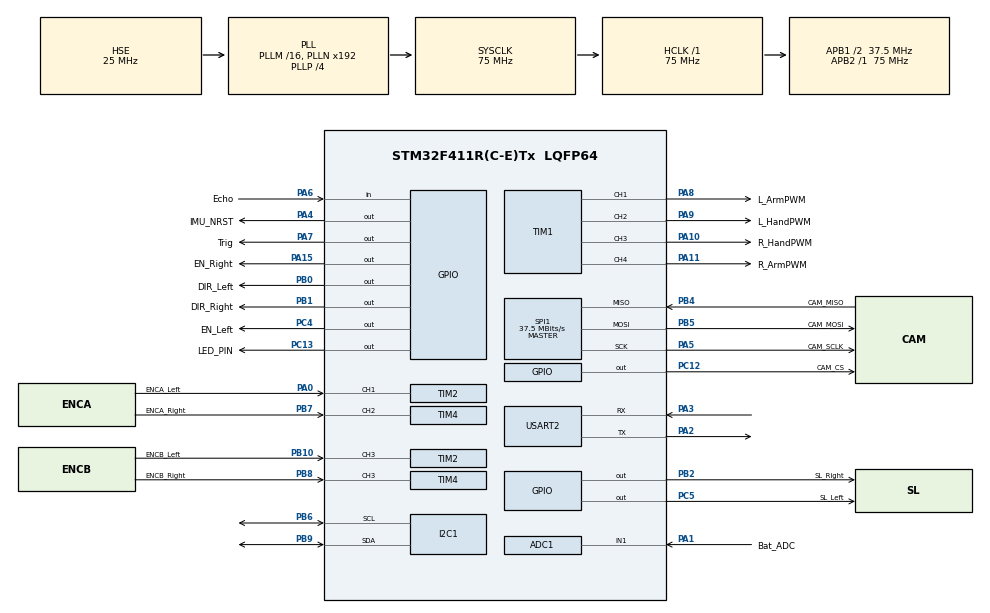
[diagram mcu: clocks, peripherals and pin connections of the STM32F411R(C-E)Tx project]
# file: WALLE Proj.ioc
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ADC1.Channel-0\#ChannelRegularConversion=ADC_CHANNEL_1
ADC1.NbrOfConversionFlag=1
ADC1.Rank-0\#ChannelRegularConversion=1
ADC1.SamplingTime-0\#ChannelRegularConversion=ADC_SAMPLETIME_3CYCLES
ADC1.master=1
Mcu.Family=STM32F4
Mcu.Name=STM32F411R(C-E)Tx
Mcu.Package=LQFP64
NVIC.PriorityGroup=NVIC_PRIORITYGROUP_4
NVIC.RCC_IRQn=true\:0\:0\:false\:false\:true\:true\:false\:true
NVIC.TIM5_IRQn=true\:0\:0\:false\:false\:true\:true\:true\:true
PA0-WKUP.GPIO_Label=ENCA_Left
PA0-WKUP.Signal=S_TIM2_CH1_ETR
PA1.GPIO_Label=Bat_ADC
PA1.Signal=ADCx_IN1
PA10.GPIO_Label=R_HandPWM
PA10.Signal=S_TIM1_CH3
PA11.GPIO_Label=R_ArmPWM
PA11.Signal=S_TIM1_CH4
PA13.Mode=Trace_Asynchronous_SW
PA13.Signal=SYS_JTMS-SWDIO
PA14.Mode=Trace_Asynchronous_SW
PA14.Signal=SYS_JTCK-SWCLK
PA15.GPIO_Label=EN_Right
PA15.Signal=GPIO_Output
PA2.Mode=Asynchronous
PA2.Signal=USART2_TX
PA3.Mode=Asynchronous
PA3.Signal=USART2_RX
PA4.GPIO_Label=IMU_NRST
PA4.Signal=GPIO_Output
PA5.GPIO_Label=CAM_SCLK
PA5.Mode=Full_Duplex_Master
PA5.Signal=SPI1_SCK
PA6.GPIO_Label=Echo
PA6.Signal=GPIO_Input
PA7.GPIO_Label=Trig
PA7.Signal=GPIO_Output
PA8.GPIO_Label=L_ArmPWM
PA8.Signal=S_TIM1_CH1
PA9.GPIO_Label=L_HandPWM
PA9.Signal=S_TIM1_CH2
PB0.GPIO_Label=DIR_Left
PB0.Signal=GPIO_Output
PB1.GPIO_Label=DIR_Right
PB1.Signal=GPIO_Output
PB10.GPIO_Label=ENCB_Left
PB10.Signal=S_TIM2_CH3
PB2.GPIO_Label=SL_Right
PB2.Signal=GPIO_Output
PB3.Mode=Trace_Asynchronous_SW
PB3.Signal=SYS_JTDO-SWO
PB4.GPIO_Label=CAM_MISO
PB4.Mode=Full_Duplex_Master
PB4.Signal=SPI1_MISO
PB5.GPIO_Label=CAM_MOSI
PB5.Mode=Full_Duplex_Master
PB5.Signal=SPI1_MOSI
PB6.Mode=I2C
PB6.Signal=I2C1_SCL
PB7.GPIO_Label=ENCA_Right
PB7.Signal=S_TIM4_CH2
PB8.GPIO_Label=ENCB_Right
PB8.Signal=S_TIM4_CH3
PB9.Mode=I2C
PB9.Signal=I2C1_SDA
PC12.GPIO_Label=CAM_CS
PC12.Signal=GPIO_Output
PC13-ANTI_TAMP.GPIO_Label=LED_PIN
PC13-ANTI_TAMP.Signal=GPIO_Output
PC4.GPIO_Label=EN_Left
PC4.Signal=GPIO_Output
PC5.GPIO_Label=SL_Left
PC5.Signal=GPIO_Output
PH0\ -\ OSC_IN.Mode=HSE-External-Oscillator
PH0\ -\ OSC_IN.Signal=RCC_OSC_IN
PH1\ -\ OSC_OUT.Mode=HSE-External-Oscillator
PH1\ -\ OSC_OUT.Signal=RCC_OSC_OUT
ProjectManager.HeapSize=0x200
ProjectManager.StackSize=0x400
ProjectManager.TargetToolchain=STM32CubeIDE
RCC.48MHZClocksFreq_Value=75000000
RCC.AHBFreq_Value=75000000
RCC.APB1CLKDivider=RCC_HCLK_DIV2
RCC.APB1Freq_Value=37500000
RCC.APB1TimFreq_Value=75000000
RCC.APB2Freq_Value=75000000
RCC.APB2TimFreq_Value=75000000
RCC.CortexFreq_Value=75000000
RCC.HCLKFreq_Value=75000000
RCC.HSE_VALUE=25000000
RCC.HSI_VALUE=16000000
RCC.LSE_VALUE=32768
RCC.PLLP=RCC_PLLP_DIV4
RCC.PLLSourceVirtual=RCC_PLLSOURCE_HSE
RCC.SYSCLKFreq_VALUE=75000000
RCC.SYSCLKSource=RCC_SYSCLKSOURCE_PLLCLK
RCC.VCOOutputFreq_Value=300000000
SH.ADCx_IN1.0=ADC1_IN1,IN1
SH.S_TIM1_CH1.0=TIM1_CH1,PWM Generation1 CH1
SH.S_TIM1_CH2.0=TIM1_CH2,PWM Generation2 CH2
SH.S_TIM1_CH3.0=TIM1_CH3,PWM Generation3 CH3
SH.S_TIM1_CH4.0=TIM1_CH4,PWM Generation4 CH4
SH.S_TIM2_CH1_ETR.0=TIM2_CH1,Input_Capture1_from_TI1
SH.S_TIM2_CH3.0=TIM2_CH3,Input_Capture3_from_TI3
SH.S_TIM4_CH2.0=TIM4_CH2,Input_Capture2_from_TI2
SH.S_TIM4_CH3.0=TIM4_CH3,Input_Capture3_from_TI3
SPI1.BaudRatePrescaler=SPI_BAUDRATEPRESCALER_2
SPI1.CalculateBaudRate=37.5 MBits/s
SPI1.Direction=SPI_DIRECTION_2LINES
SPI1.Mode=SPI_MODE_MASTER
SPI1.VirtualType=VM_MASTER
TIM1.Channel-PWM\ Generation1\ CH1=TIM_CHANNEL_1
TIM1.Channel-PWM\ Generation2\ CH2=TIM_CHANNEL_2
TIM1.Channel-PWM\ Generation3\ CH3=TIM_CHANNEL_3
TIM1.Channel-PWM\ Generation4\ CH4=TIM_CHANNEL_4
TIM2.Channel-Input_Capture1_from_TI1=TIM_CHANNEL_1
TIM2.Channel-Input_Capture3_from_TI3=TIM_CHANNEL_3
TIM4.Channel-Input_Capture2_from_TI2=TIM_CHANNEL_2
TIM4.Channel-Input_Capture3_from_TI3=TIM_CHANNEL_3
TIM5.Period=99
TIM5.Prescaler=15
USART2.VirtualMode=VM_ASYNC
VP_TIM3_VS_ClockSourceINT.Mode=Internal
VP_TIM5_VS_ClockSourceINT.Mode=Internal
board=custom

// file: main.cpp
/* USER CODE BEGIN Header */
/**
  ******************************************************************************
  * @file           : main.c
  * @brief          : Main program body
  ******************************************************************************
  * @attention
  *
  * Copyright (c) 2025 STMicroelectronics.
  * All rights reserved.
  *
  * This software is licensed under terms that can be found in the LICENSE file
  * in the root directory of this software component.
  * If no LICENSE file comes with this software, it is provided AS-IS.
  *
  ******************************************************************************
  */
/* USER CODE END Header */
#include "main.h"
#include "main.h"
#include "batteryMonitor.h"
#include "WALLE_FSM.h"
#include <string.h>
#include <unistd.h>
#include <stdio.h>

ADC_HandleTypeDef hadc1;

I2C_HandleTypeDef hi2c1;

SPI_HandleTypeDef hspi1;

TIM_HandleTypeDef htim1;
TIM_HandleTypeDef htim2;
TIM_HandleTypeDef htim3;
TIM_HandleTypeDef htim4;
TIM_HandleTypeDef htim5;

UART_HandleTypeDef huart2;

/*Global Motors for interrupt updates*/
RomiMotor rightMotor(GPIOA, EN_Right_Pin, GPIOB, DIR_Right_Pin, GPIOB, SL_Right_Pin);
RomiMotor leftMotor(GPIOC, EN_Left_Pin, GPIOB, DIR_Left_Pin, GPIOC, SL_Left_Pin);

void SystemClock_Config(void);
static void MX_GPIO_Init(void);
static void MX_ADC1_Init(void);
static void MX_I2C1_Init(void);
static void MX_TIM1_Init(void);
static void MX_TIM2_Init(void);
static void MX_TIM4_Init(void);
static void MX_USART2_UART_Init(void);
static void MX_TIM3_Init(void);
static void MX_SPI1_Init(void);
static void MX_TIM5_Init(void);

#ifndef WALL_E_FUNC
#define WALL_E_FUNC
void WALL_E_systemCheck(BatteryMonitor&, HCSR04&, RomiMotor&, RomiMotor&, BNO055&, OV2640Camera&);
#endif
/* USER CODE BEGIN PFP */
#define OV2640_I2C_ADDR 0x60  // 0x30 << 1

/* USER CODE END PFP */

/* USER CODE BEGIN 0 */
void printToUART(const char* msg) {
    HAL_UART_Transmit(&huart2, (uint8_t*)msg, strlen(msg), HAL_MAX_DELAY);
}

void simpleMovements(){
	rightMotor.setSpeed(10);
	leftMotor.setSpeed(-10);
	HAL_Delay(1000);
	rightMotor.setSpeed(-5);
	HAL_Delay(500);
	rightMotor.setSpeed(10);
	HAL_Delay(700);
	leftMotor.setSpeed(0);
	rightMotor.setSpeed(0);
}
/* USER CODE END 0 */

int main(void)
{

  /* MCU Configuration--------------------------------------------------------*/

  /* Reset of all peripherals, Initializes the Flash interface and the Systick. */
  HAL_Init();

  /* Configure the system clock */
  SystemClock_Config();

  /* Initialize all configured peripherals */
  MX_GPIO_Init();
  MX_ADC1_Init();
  MX_I2C1_Init();
  MX_TIM1_Init();
  MX_TIM2_Init();
  MX_TIM4_Init();
  MX_USART2_UART_Init();
  MX_TIM3_Init();
  MX_SPI1_Init();
  MX_TIM5_Init();

  HAL_NVIC_SetPriority(TIM5_IRQn, 0, 0);
  HAL_NVIC_EnableIRQ(TIM5_IRQn);

  /*Peripherals Instantiation*/
  BatteryMonitor batteryMonitor(&hadc1, 7000);
  HCSR04 rangeFinder(GPIOA, Trig_Pin, Echo_GPIO_Port, Echo_Pin, &htim3);
  BNO055 imu(&hi2c1, (uint8_t) 0x28);
  OV2640Camera camera(&hi2c1, &hspi1, GPIOC, CAM_CS_Pin);
  Servo rightArm(&htim1, TIM_CHANNEL_4);
  Servo rightHand(&htim1, TIM_CHANNEL_3);
  Servo leftArm(&htim1, TIM_CHANNEL_1);
  Servo leftHand(&htim1, TIM_CHANNEL_2);
  rightArm.attach();
  rightHand.attach();
  leftArm.attach();
  leftHand.attach();

  WALL_E_systemCheck(batteryMonitor, rangeFinder, rightMotor, leftMotor, imu, camera);
  printToUART("Entering WALL-E FSM\r\n");

  WALLE walleFSM(imu, rangeFinder, leftMotor, rightMotor, camera, leftArm, leftHand,
		  rightArm, rightHand);

  walleFSM.init();
  uint32_t lastTick = HAL_GetTick();

  while(1){
	  uint32_t currentTick = HAL_GetTick();
	  float dt = (currentTick - lastTick);
	  lastTick = currentTick;

	  walleFSM.update(dt);

	  HAL_Delay(5);
  }

}

/*
 * @brief Function Performs System Peipherals Check
 * @return None
 */
void WALL_E_systemCheck(BatteryMonitor& bat, HCSR04& range, RomiMotor& rMotor, RomiMotor& lMotor, BNO055& imu, OV2640Camera& camera){
	  imu.init_imu();
	  char buffer[1024];
	  uint8_t sys, gyro, accel, mag;
	  while (true) {
		  imu.readCalibStatus(sys, gyro, accel, mag);
		  if (sys == 3 && gyro == 3){
			  int len = sprintf(buffer, "IMU Calibrated Sys: %d Gyro: %d\r\n", sys, gyro);
			  HAL_UART_Transmit(&huart2, (uint8_t *)buffer, len, 10);
			  memset(buffer, 0, sizeof(buffer));
			  break;
		  }
		  int len = sprintf(buffer, "Sys %d, Gyro %d, Accel %d, Mag %d\r\n", sys, gyro, accel, mag);
		  HAL_UART_Transmit(&huart2, (uint8_t *)buffer, len, 10);
		  memset(buffer, 0, sizeof(buffer));
		  HAL_Delay(500);
	  }

	  /*UltraSonic Sensor Timer*/
	  HAL_TIM_Base_Start(&htim3);

	  /*Interrupt Timer for PWM Signal for Motors*/
	  rMotor.enable();
	  rMotor.setSpeed(0);
	  lMotor.enable();
	  lMotor.setSpeed(0);
	  HAL_TIM_Base_Start_IT(&htim5);
	  int len = sprintf(buffer, "Motors Enabled, Speed Set to 0.\r\n");
	  HAL_UART_Transmit(&huart2, (uint8_t *)buffer, len, 10);
	  memset(buffer, 0, sizeof(buffer));

	  /*Battery Check*/
	  len = sprintf(buffer, "Battery Voltage is at %u mV\r\nChecking RangeSensor\r\n", bat.getVoltage_mV());
	  HAL_UART_Transmit(&huart2, (uint8_t *)buffer, len, 10);
	  memset(buffer, 0, sizeof(buffer));

	  /*Range Sensor Check*/
	  while(true){
		  bool success = range.measure();
		  if (success){
				  uint32_t d = range.getDistanceCm();
				  len = sprintf(buffer, "\tDistance is %lu cm\r\n", d);
				  HAL_UART_Transmit(&huart2, (uint8_t *)buffer, len, 10);
				  memset(buffer, 0, sizeof(buffer));
				  break;
		  HAL_Delay(500);
		  }
	  }

	  /*Camera Check*/
	  printToUART("Camera I2C Check and initialization\r\n");
	  uint8_t pid = 0, ver = 0;
	  HAL_I2C_Mem_Read(&hi2c1, OV2640_I2C_ADDR, 0x0A, I2C_MEMADD_SIZE_8BIT, &pid, 1, HAL_MAX_DELAY);
	  HAL_I2C_Mem_Read(&hi2c1, OV2640_I2C_ADDR, 0x0B, I2C_MEMADD_SIZE_8BIT, &ver, 1, HAL_MAX_DELAY);

	  char buf[64];
	  snprintf(buf, sizeof(buf), "\tOV2640 PID: 0x%02X, VER: 0x%02X\r\n", pid, ver);
	  HAL_UART_Transmit(&huart2, (uint8_t*)buf, strlen(buf), HAL_MAX_DELAY);
	  while(true){
		  bool success = camera.initialize();
		  if (success){
			  printToUART("\tCamera Initialized. Ready to Detect\r\n");
			  break;
		  }
	  }

}

/*
 * @brief Function is the interrupt Callback for the Updates on the Motor PWM signals
 * @return None
 */
void HAL_TIM_PeriodElapsedCallback(TIM_HandleTypeDef *htim) {
    if (htim->Instance == TIM5) {
        // Your motor PWM logic here
    	rightMotor.updatePWM();
        leftMotor.updatePWM();
    }
}
void SystemClock_Config(void)
{
  RCC_OscInitTypeDef RCC_OscInitStruct = {0};
  RCC_ClkInitTypeDef RCC_ClkInitStruct = {0};

  /** Configure the main internal regulator output voltage
  */
  __HAL_RCC_PWR_CLK_ENABLE();
  __HAL_PWR_VOLTAGESCALING_CONFIG(PWR_REGULATOR_VOLTAGE_SCALE1);

  /** Initializes the RCC Oscillators according to the specified parameters
  * in the RCC_OscInitTypeDef structure.
  */
  RCC_OscInitStruct.OscillatorType = RCC_OSCILLATORTYPE_HSE;
  RCC_OscInitStruct.HSEState = RCC_HSE_ON;
  RCC_OscInitStruct.PLL.PLLState = RCC_PLL_ON;
  RCC_OscInitStruct.PLL.PLLSource = RCC_PLLSOURCE_HSE;
  RCC_OscInitStruct.PLL.PLLM = 16;
  RCC_OscInitStruct.PLL.PLLN = 192;
  RCC_OscInitStruct.PLL.PLLP = RCC_PLLP_DIV4;
  RCC_OscInitStruct.PLL.PLLQ = 4;
  if (HAL_RCC_OscConfig(&RCC_OscInitStruct) != HAL_OK)
  {
    Error_Handler();
  }

  /** Initializes the CPU, AHB and APB buses clocks
  */
  RCC_ClkInitStruct.ClockType = RCC_CLOCKTYPE_HCLK|RCC_CLOCKTYPE_SYSCLK
                              |RCC_CLOCKTYPE_PCLK1|RCC_CLOCKTYPE_PCLK2;
  RCC_ClkInitStruct.SYSCLKSource = RCC_SYSCLKSOURCE_PLLCLK;
  RCC_ClkInitStruct.AHBCLKDivider = RCC_SYSCLK_DIV1;
  RCC_ClkInitStruct.APB1CLKDivider = RCC_HCLK_DIV2;
  RCC_ClkInitStruct.APB2CLKDivider = RCC_HCLK_DIV1;

  if (HAL_RCC_ClockConfig(&RCC_ClkInitStruct, FLASH_LATENCY_2) != HAL_OK)
  {
    Error_Handler();
  }
}

static void MX_ADC1_Init(void)
{

  ADC_ChannelConfTypeDef sConfig = {0};

  /** Configure the global features of the ADC (Clock, Resolution, Data Alignment and number of conversion)
  */
  hadc1.Instance = ADC1;
  hadc1.Init.ClockPrescaler = ADC_CLOCK_SYNC_PCLK_DIV4;
  hadc1.Init.Resolution = ADC_RESOLUTION_12B;
  hadc1.Init.ScanConvMode = DISABLE;
  hadc1.Init.ContinuousConvMode = DISABLE;
  hadc1.Init.DiscontinuousConvMode = DISABLE;
  hadc1.Init.ExternalTrigConvEdge = ADC_EXTERNALTRIGCONVEDGE_NONE;
  hadc1.Init.ExternalTrigConv = ADC_SOFTWARE_START;
  hadc1.Init.DataAlign = ADC_DATAALIGN_RIGHT;
  hadc1.Init.NbrOfConversion = 1;
  hadc1.Init.DMAContinuousRequests = DISABLE;
  hadc1.Init.EOCSelection = ADC_EOC_SINGLE_CONV;
  if (HAL_ADC_Init(&hadc1) != HAL_OK)
  {
    Error_Handler();
  }

  /** Configure for the selected ADC regular channel its corresponding rank in the sequencer and its sample time.
  */
  sConfig.Channel = ADC_CHANNEL_1;
  sConfig.Rank = 1;
  sConfig.SamplingTime = ADC_SAMPLETIME_3CYCLES;
  if (HAL_ADC_ConfigChannel(&hadc1, &sConfig) != HAL_OK)
  {
    Error_Handler();
  }

}

static void MX_I2C1_Init(void)
{

  hi2c1.Instance = I2C1;
  hi2c1.Init.ClockSpeed = 100000;
  hi2c1.Init.DutyCycle = I2C_DUTYCYCLE_2;
  hi2c1.Init.OwnAddress1 = 0;
  hi2c1.Init.AddressingMode = I2C_ADDRESSINGMODE_7BIT;
  hi2c1.Init.DualAddressMode = I2C_DUALADDRESS_DISABLE;
  hi2c1.Init.OwnAddress2 = 0;
  hi2c1.Init.GeneralCallMode = I2C_GENERALCALL_DISABLE;
  hi2c1.Init.NoStretchMode = I2C_NOSTRETCH_DISABLE;
  if (HAL_I2C_Init(&hi2c1) != HAL_OK)
  {
    Error_Handler();
  }

}

static void MX_SPI1_Init(void)
{

  /* SPI1 parameter configuration*/
  hspi1.Instance = SPI1;
  hspi1.Init.Mode = SPI_MODE_MASTER;
  hspi1.Init.Direction = SPI_DIRECTION_2LINES;
  hspi1.Init.DataSize = SPI_DATASIZE_8BIT;
  hspi1.Init.CLKPolarity = SPI_POLARITY_LOW;
  hspi1.Init.CLKPhase = SPI_PHASE_1EDGE;
  hspi1.Init.NSS = SPI_NSS_SOFT;
  hspi1.Init.BaudRatePrescaler = SPI_BAUDRATEPRESCALER_2;
  hspi1.Init.FirstBit = SPI_FIRSTBIT_MSB;
  hspi1.Init.TIMode = SPI_TIMODE_DISABLE;
  hspi1.Init.CRCCalculation = SPI_CRCCALCULATION_DISABLE;
  hspi1.Init.CRCPolynomial = 10;
  if (HAL_SPI_Init(&hspi1) != HAL_OK)
  {
    Error_Handler();
  }

}

static void MX_TIM1_Init(void)
{

  TIM_MasterConfigTypeDef sMasterConfig = {0};
  TIM_OC_InitTypeDef sConfigOC = {0};
  TIM_BreakDeadTimeConfigTypeDef sBreakDeadTimeConfig = {0};

  htim1.Instance = TIM1;
  htim1.Init.Prescaler = 74;
  htim1.Init.CounterMode = TIM_COUNTERMODE_UP;
  htim1.Init.Period = 19999;
  htim1.Init.ClockDivision = TIM_CLOCKDIVISION_DIV1;
  htim1.Init.RepetitionCounter = 0;
  htim1.Init.AutoReloadPreload = TIM_AUTORELOAD_PRELOAD_DISABLE;
  if (HAL_TIM_PWM_Init(&htim1) != HAL_OK)
  {
    Error_Handler();
  }
  sMasterConfig.MasterOutputTrigger = TIM_TRGO_RESET;
  sMasterConfig.MasterSlaveMode = TIM_MASTERSLAVEMODE_DISABLE;
  if (HAL_TIMEx_MasterConfigSynchronization(&htim1, &sMasterConfig) != HAL_OK)
  {
    Error_Handler();
  }
  sConfigOC.OCMode = TIM_OCMODE_PWM1;
  sConfigOC.Pulse = 0;
  sConfigOC.OCPolarity = TIM_OCPOLARITY_HIGH;
  sConfigOC.OCNPolarity = TIM_OCNPOLARITY_HIGH;
  sConfigOC.OCFastMode = TIM_OCFAST_DISABLE;
  sConfigOC.OCIdleState = TIM_OCIDLESTATE_RESET;
  sConfigOC.OCNIdleState = TIM_OCNIDLESTATE_RESET;
  if (HAL_TIM_PWM_ConfigChannel(&htim1, &sConfigOC, TIM_CHANNEL_1) != HAL_OK)
  {
    Error_Handler();
  }
  if (HAL_TIM_PWM_ConfigChannel(&htim1, &sConfigOC, TIM_CHANNEL_2) != HAL_OK)
  {
    Error_Handler();
  }
  if (HAL_TIM_PWM_ConfigChannel(&htim1, &sConfigOC, TIM_CHANNEL_3) != HAL_OK)
  {
    Error_Handler();
  }
  if (HAL_TIM_PWM_ConfigChannel(&htim1, &sConfigOC, TIM_CHANNEL_4) != HAL_OK)
  {
    Error_Handler();
  }
  sBreakDeadTimeConfig.OffStateRunMode = TIM_OSSR_DISABLE;
  sBreakDeadTimeConfig.OffStateIDLEMode = TIM_OSSI_DISABLE;
  sBreakDeadTimeConfig.LockLevel = TIM_LOCKLEVEL_OFF;
  sBreakDeadTimeConfig.DeadTime = 0;
  sBreakDeadTimeConfig.BreakState = TIM_BREAK_DISABLE;
  sBreakDeadTimeConfig.BreakPolarity = TIM_BREAKPOLARITY_HIGH;
  sBreakDeadTimeConfig.AutomaticOutput = TIM_AUTOMATICOUTPUT_DISABLE;
  if (HAL_TIMEx_ConfigBreakDeadTime(&htim1, &sBreakDeadTimeConfig) != HAL_OK)
  {
    Error_Handler();
  }
  HAL_TIM_MspPostInit(&htim1);

}

static void MX_TIM2_Init(void)
{

  TIM_MasterConfigTypeDef sMasterConfig = {0};
  TIM_IC_InitTypeDef sConfigIC = {0};

  htim2.Instance = TIM2;
  htim2.Init.Prescaler = 0;
  htim2.Init.CounterMode = TIM_COUNTERMODE_UP;
  htim2.Init.Period = 4294967295;
  htim2.Init.ClockDivision = TIM_CLOCKDIVISION_DIV1;
  htim2.Init.AutoReloadPreload = TIM_AUTORELOAD_PRELOAD_DISABLE;
  if (HAL_TIM_IC_Init(&htim2) != HAL_OK)
  {
    Error_Handler();
  }
  sMasterConfig.MasterOutputTrigger = TIM_TRGO_RESET;
  sMasterConfig.MasterSlaveMode = TIM_MASTERSLAVEMODE_DISABLE;
  if (HAL_TIMEx_MasterConfigSynchronization(&htim2, &sMasterConfig) != HAL_OK)
  {
    Error_Handler();
  }
  sConfigIC.ICPolarity = TIM_INPUTCHANNELPOLARITY_RISING;
  sConfigIC.ICSelection = TIM_ICSELECTION_DIRECTTI;
  sConfigIC.ICPrescaler = TIM_ICPSC_DIV1;
  sConfigIC.ICFilter = 0;
  if (HAL_TIM_IC_ConfigChannel(&htim2, &sConfigIC, TIM_CHANNEL_1) != HAL_OK)
  {
    Error_Handler();
  }
  if (HAL_TIM_IC_ConfigChannel(&htim2, &sConfigIC, TIM_CHANNEL_3) != HAL_OK)
  {
    Error_Handler();
  }

}

static void MX_TIM3_Init(void)
{

  TIM_ClockConfigTypeDef sClockSourceConfig = {0};
  TIM_MasterConfigTypeDef sMasterConfig = {0};

  htim3.Instance = TIM3;
  htim3.Init.Prescaler = 0;
  htim3.Init.CounterMode = TIM_COUNTERMODE_UP;
  htim3.Init.Period = 65535;
  htim3.Init.ClockDivision = TIM_CLOCKDIVISION_DIV1;
  htim3.Init.AutoReloadPreload = TIM_AUTORELOAD_PRELOAD_DISABLE;
  if (HAL_TIM_Base_Init(&htim3) != HAL_OK)
  {
    Error_Handler();
  }
  sClockSourceConfig.ClockSource = TIM_CLOCKSOURCE_INTERNAL;
  if (HAL_TIM_ConfigClockSource(&htim3, &sClockSourceConfig) != HAL_OK)
  {
    Error_Handler();
  }
  sMasterConfig.MasterOutputTrigger = TIM_TRGO_RESET;
  sMasterConfig.MasterSlaveMode = TIM_MASTERSLAVEMODE_DISABLE;
  if (HAL_TIMEx_MasterConfigSynchronization(&htim3, &sMasterConfig) != HAL_OK)
  {
    Error_Handler();
  }

}

static void MX_TIM4_Init(void)
{

  TIM_MasterConfigTypeDef sMasterConfig = {0};
  TIM_IC_InitTypeDef sConfigIC = {0};

  htim4.Instance = TIM4;
  htim4.Init.Prescaler = 0;
  htim4.Init.CounterMode = TIM_COUNTERMODE_UP;
  htim4.Init.Period = 65535;
  htim4.Init.ClockDivision = TIM_CLOCKDIVISION_DIV1;
  htim4.Init.AutoReloadPreload = TIM_AUTORELOAD_PRELOAD_DISABLE;
  if (HAL_TIM_IC_Init(&htim4) != HAL_OK)
  {
    Error_Handler();
  }
  sMasterConfig.MasterOutputTrigger = TIM_TRGO_RESET;
  sMasterConfig.MasterSlaveMode = TIM_MASTERSLAVEMODE_DISABLE;
  if (HAL_TIMEx_MasterConfigSynchronization(&htim4, &sMasterConfig) != HAL_OK)
  {
    Error_Handler();
  }
  sConfigIC.ICPolarity = TIM_INPUTCHANNELPOLARITY_RISING;
  sConfigIC.ICSelection = TIM_ICSELECTION_DIRECTTI;
  sConfigIC.ICPrescaler = TIM_ICPSC_DIV1;
  sConfigIC.ICFilter = 0;
  if (HAL_TIM_IC_ConfigChannel(&htim4, &sConfigIC, TIM_CHANNEL_2) != HAL_OK)
  {
    Error_Handler();
  }
  if (HAL_TIM_IC_ConfigChannel(&htim4, &sConfigIC, TIM_CHANNEL_3) != HAL_OK)
  {
    Error_Handler();
  }

}

static void MX_TIM5_Init(void)
{

  TIM_ClockConfigTypeDef sClockSourceConfig = {0};
  TIM_MasterConfigTypeDef sMasterConfig = {0};

  htim5.Instance = TIM5;
  htim5.Init.Prescaler = 15;
  htim5.Init.CounterMode = TIM_COUNTERMODE_UP;
  htim5.Init.Period = 99;
  htim5.Init.ClockDivision = TIM_CLOCKDIVISION_DIV1;
  htim5.Init.AutoReloadPreload = TIM_AUTORELOAD_PRELOAD_DISABLE;
  if (HAL_TIM_Base_Init(&htim5) != HAL_OK)
  {
    Error_Handler();
  }
  sClockSourceConfig.ClockSource = TIM_CLOCKSOURCE_INTERNAL;
  if (HAL_TIM_ConfigClockSource(&htim5, &sClockSourceConfig) != HAL_OK)
  {
    Error_Handler();
  }
  sMasterConfig.MasterOutputTrigger = TIM_TRGO_RESET;
  sMasterConfig.MasterSlaveMode = TIM_MASTERSLAVEMODE_DISABLE;
  if (HAL_TIMEx_MasterConfigSynchronization(&htim5, &sMasterConfig) != HAL_OK)
  {
    Error_Handler();
  }

}

static void MX_USART2_UART_Init(void)
{

  huart2.Instance = USART2;
  huart2.Init.BaudRate = 115200;
  huart2.Init.WordLength = UART_WORDLENGTH_8B;
  huart2.Init.StopBits = UART_STOPBITS_1;
  huart2.Init.Parity = UART_PARITY_NONE;
  huart2.Init.Mode = UART_MODE_TX_RX;
  huart2.Init.HwFlowCtl = UART_HWCONTROL_NONE;
  huart2.Init.OverSampling = UART_OVERSAMPLING_16;
  if (HAL_UART_Init(&huart2) != HAL_OK)
  {
    Error_Handler();
  }

}

static void MX_GPIO_Init(void)
{
  GPIO_InitTypeDef GPIO_InitStruct = {0};

  /* GPIO Ports Clock Enable */
  __HAL_RCC_GPIOC_CLK_ENABLE();
  __HAL_RCC_GPIOH_CLK_ENABLE();
  __HAL_RCC_GPIOA_CLK_ENABLE();
  __HAL_RCC_GPIOB_CLK_ENABLE();

  /*Configure GPIO pin Output Level */
  HAL_GPIO_WritePin(GPIOC, LED_PIN_Pin|EN_Left_Pin|SL_Left_Pin|CAM_CS_Pin, GPIO_PIN_RESET);

  /*Configure GPIO pin Output Level */
  HAL_GPIO_WritePin(GPIOA, IMU_NRST_Pin|Trig_Pin|EN_Right_Pin, GPIO_PIN_RESET);

  /*Configure GPIO pin Output Level */
  HAL_GPIO_WritePin(GPIOB, DIR_Left_Pin|DIR_Right_Pin|SL_Right_Pin, GPIO_PIN_RESET);

  /*Configure GPIO pins : LED_PIN_Pin EN_Left_Pin SL_Left_Pin CAM_CS_Pin */
  GPIO_InitStruct.Pin = LED_PIN_Pin|EN_Left_Pin|SL_Left_Pin|CAM_CS_Pin;
  GPIO_InitStruct.Mode = GPIO_MODE_OUTPUT_PP;
  GPIO_InitStruct.Pull = GPIO_NOPULL;
  GPIO_InitStruct.Speed = GPIO_SPEED_FREQ_LOW;
  HAL_GPIO_Init(GPIOC, &GPIO_InitStruct);

  /*Configure GPIO pins : IMU_NRST_Pin Trig_Pin EN_Right_Pin */
  GPIO_InitStruct.Pin = IMU_NRST_Pin|Trig_Pin|EN_Right_Pin;
  GPIO_InitStruct.Mode = GPIO_MODE_OUTPUT_PP;
  GPIO_InitStruct.Pull = GPIO_NOPULL;
  GPIO_InitStruct.Speed = GPIO_SPEED_FREQ_LOW;
  HAL_GPIO_Init(GPIOA, &GPIO_InitStruct);

  /*Configure GPIO pin : Echo_Pin */
  GPIO_InitStruct.Pin = Echo_Pin;
  GPIO_InitStruct.Mode = GPIO_MODE_INPUT;
  GPIO_InitStruct.Pull = GPIO_NOPULL;
  HAL_GPIO_Init(Echo_GPIO_Port, &GPIO_InitStruct);

  /*Configure GPIO pins : DIR_Left_Pin DIR_Right_Pin SL_Right_Pin */
  GPIO_InitStruct.Pin = DIR_Left_Pin|DIR_Right_Pin|SL_Right_Pin;
  GPIO_InitStruct.Mode = GPIO_MODE_OUTPUT_PP;
  GPIO_InitStruct.Pull = GPIO_NOPULL;
  GPIO_InitStruct.Speed = GPIO_SPEED_FREQ_LOW;
  HAL_GPIO_Init(GPIOB, &GPIO_InitStruct);

}

void Error_Handler(void)
{
  __disable_irq();
  while (1)
  {
  }
}
